# M440 register map
File version: 0.1
Registers are 32-bit, read-write, reset 0x0 unless marked. A register's access mark holds for its fields unless they carry their own. Offsets are from the block's base; [hi:lo] are bit positions; {n}, {i} and the like mark numbered series.

## UART0 — UART
Base 0x44048000
Same registers: UART1 0x44049000
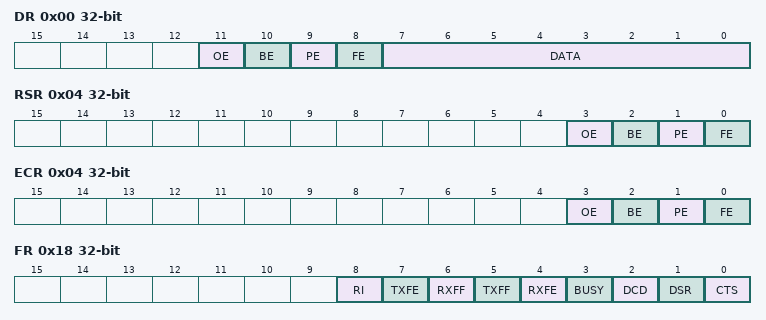
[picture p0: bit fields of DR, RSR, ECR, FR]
0x00 DR — Data Register
  [11] OE ro, [10] BE ro, [9] PE ro, [8] FE ro, [7:0] DATA
0x04 RSR ro — Receive Status Register
  [3] OE, [2] BE, [1] PE, [0] FE
0x04 ECR wo — Error Clear Register
  [3] OE, [2] BE, [1] PE, [0] FE
0x18 FR ro — Flag Register
  [8] RI, [7] TXFE, [6] RXFF, [5] TXFF, [4] RXFE, [3] BUSY, [2] DCD, [1] DSR, [0] CTS
0x24 IBRD — Integer Baud Rate Register
  [15:0] BAUDDIVINT
0x28 FBRD — Fractional Baud Rate Register
  [5:0] BAUDDIVFRAC
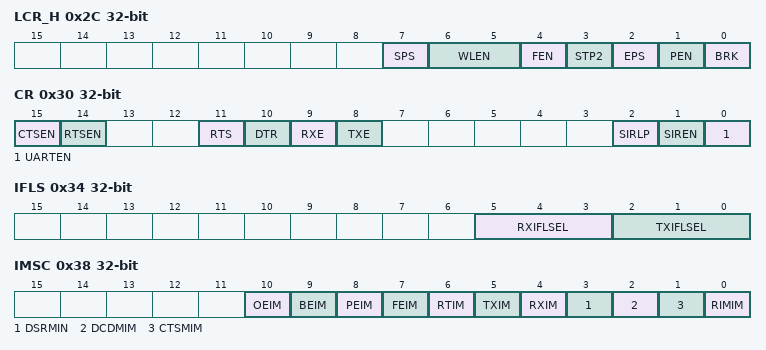
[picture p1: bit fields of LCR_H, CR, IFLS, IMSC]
0x2C LCR_H — Line Control Register
  [7] SPS, [6:5] WLEN, [4] FEN, [3] STP2, [2] EPS, [1] PEN, [0] BRK
0x30 CR — Control Register
  [15] CTSEN, [14] RTSEN, [11] RTS, [10] DTR, [9] RXE, [8] TXE, [2] SIRLP, [1] SIREN, [0] UARTEN
0x34 IFLS — Interrupt FIFO Level Select Register
  [5:3] RXIFLSEL, [2:0] TXIFLSEL
0x38 IMSC — Interrupt Mask Set_Clear Register
  [10] OEIM, [9] BEIM, [8] PEIM, [7] FEIM, [6] RTIM, [5] TXIM, [4] RXIM, [3] DSRMIN, [2] DCDMIM, [1] CTSMIM, [0] RIMIM
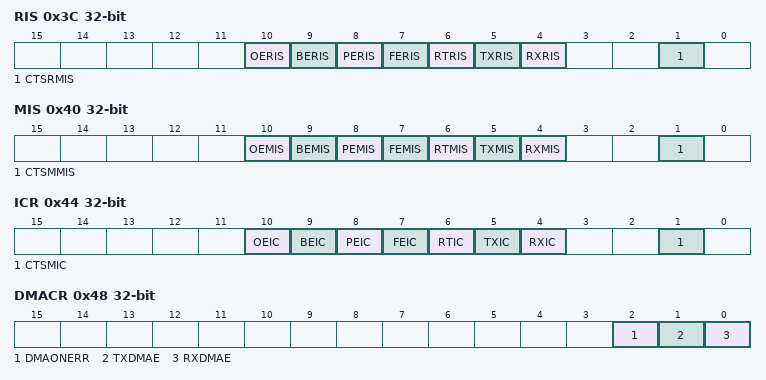
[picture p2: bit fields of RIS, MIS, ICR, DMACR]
0x3C RIS ro (reset mask 0xFFFFFFF0) — Raw Interrupt Status Register
  [10] OERIS, [9] BERIS, [8] PERIS, [7] FERIS, [6] RTRIS, [5] TXRIS, [4] RXRIS, [1] CTSRMIS
0x40 MIS ro (reset mask 0xFFFFFFF0) — Masked Interrupt Status Register
  [10] OEMIS, [9] BEMIS, [8] PEMIS, [7] FEMIS, [6] RTMIS, [5] TXMIS, [4] RXMIS, [1] CTSMMIS
0x44 ICR wo — Interrupt Clear Register
  [10] OEIC, [9] BEIC, [8] PEIC, [7] FEIC, [6] RTIC, [5] TXIC, [4] RXIC, [1] CTSMIC
0x48 DMACR — DMA Control Register
  [2] DMAONERR, [1] TXDMAE, [0] RXDMAE

## ADA — 12bit A_D Converter
Base 0x44050000
Same registers: ADB 0x44051000
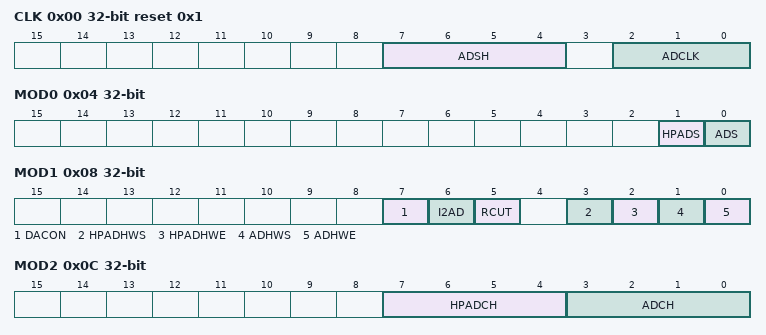
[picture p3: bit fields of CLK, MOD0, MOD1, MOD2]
0x00 CLK reset 0x1 — Conversion Clock Setting Register
  [7:4] ADSH, [2:0] ADCLK
0x04 MOD0 wo — Mode Control Register0
  [1] HPADS, [0] ADS
0x08 MOD1 — Mode Control Register1
  [7] DACON, [6] I2AD, [5] RCUT, [3] HPADHWS, [2] HPADHWE, [1] ADHWS, [0] ADHWE
0x0C MOD2 — Mode Control Register2
  [7:4] HPADCH, [3:0] ADCH
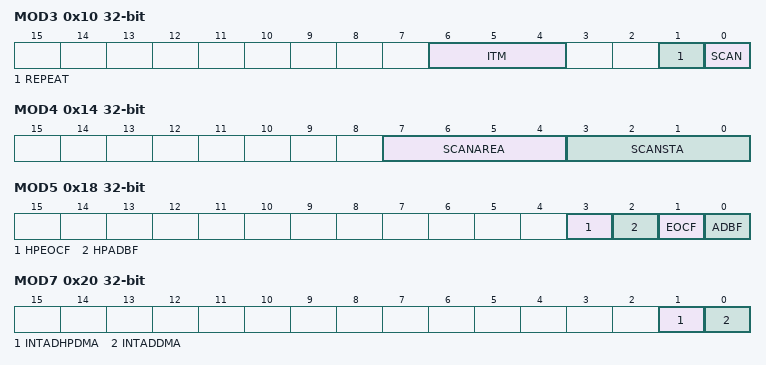
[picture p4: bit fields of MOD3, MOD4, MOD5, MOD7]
0x10 MOD3 — Mode Control Register3
  [6:4] ITM, [1] REPEAT, [0] SCAN
0x14 MOD4 — Mode Control Register4
  [7:4] SCANAREA, [3:0] SCANSTA
0x18 MOD5 ro — Mode Control Register5
  [3] HPEOCF, [2] HPADBF, [1] EOCF, [0] ADBF
0x1C MOD6 — Mode Control Register6
  [1:0] ADRST wo
0x20 MOD7 — Mode Control Register7
  [1] INTADHPDMA, [0] INTADDMA
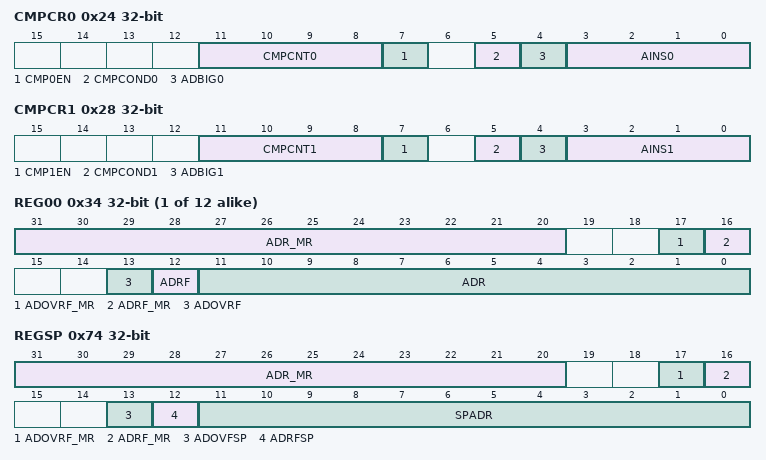
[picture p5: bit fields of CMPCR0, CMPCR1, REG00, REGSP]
0x24 CMPCR0 — Monitoring Interrupt Control Register0
  [11:8] CMPCNT0, [7] CMP0EN, [5] CMPCOND0, [4] ADBIG0, [3:0] AINS0
0x28 CMPCR1 — Monitoring Interrupt Control Register1
  [11:8] CMPCNT1, [7] CMP1EN, [5] CMPCOND1, [4] ADBIG1, [3:0] AINS1
0x2C CMP0 — Conversion Result Compare Register0
  [11:0] AD0CMP
0x30 CMP1 — Conversion Result Compare Register1
  [11:0] AD1CMP
{0x34+4i} REG{i:02} ro (i=0..11) — Conversion Result Store Register{i}
  [31:20] ADR_MR, [17] ADOVRF_MR, [16] ADRF_MR, [13] ADOVRF, [12] ADRF, [11:0] ADR
0x74 REGSP ro — Highest Priority Conversion Result Store Register
  [31:20] ADR_MR, [17] ADOVRF_MR, [16] ADRF_MR, [13] ADOVFSP, [12] ADRFSP, [11:0] SPADR

## ADC — 12bit A_D Converter
Base 0x44052000
Registers as ADA; these are added or differ:
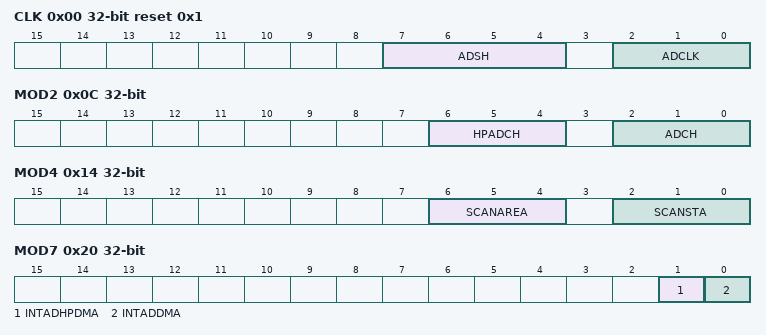
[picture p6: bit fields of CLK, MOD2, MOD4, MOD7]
0x00 CLK reset 0x1 — Conversion Clock Setting Register
  [7:4] ADSH, [2:0] ADCLK
0x0C MOD2 — Mode Control Register2
  [6:4] HPADCH, [2:0] ADCH
0x14 MOD4 — Mode Control Register4
  [6:4] SCANAREA, [2:0] SCANSTA
0x1C MOD6
  [1:0] ADRST wo
0x20 MOD7 — Mode Control Register6
  [1] INTADHPDMA, [0] INTADDMA

## AD_MIRA — 12bit A_D Converter for PSC
Base 0x40074000
Same registers: AD_MIRB 0x40079000
Registers as ADA, without CLK, MOD{n} (n=0..7), CMPCR0, CMPCR1, CMP0, CMP1, REG{n:02} (n=8..11).

## AD_MIRC — 12bit A_D Converter for PSC
Base 0x4007A000
Registers as ADA, without CLK, MOD{n} (n=0..7), CMPCR0, CMPCR1, CMP0, CMP1, REG{n:02} (n=8..11).
